# psoc4axx register map
Vendor: Cypress Semiconductor; Series: PSoC4Axx; File version: 1.0
CPU: CM0PLUS r0p1, little endian, no MPU, no FPU, VTOR, 2 interrupt priority bits
Registers are 32-bit, read-write, reset 0x0 unless marked. A register's access mark holds for its fields unless they carry their own. Offsets are from the block's base; [hi:lo] are bit positions; {n}, {i} and the like mark numbered series.

## ART0 — Analog Routing Block
Base 0x40380000
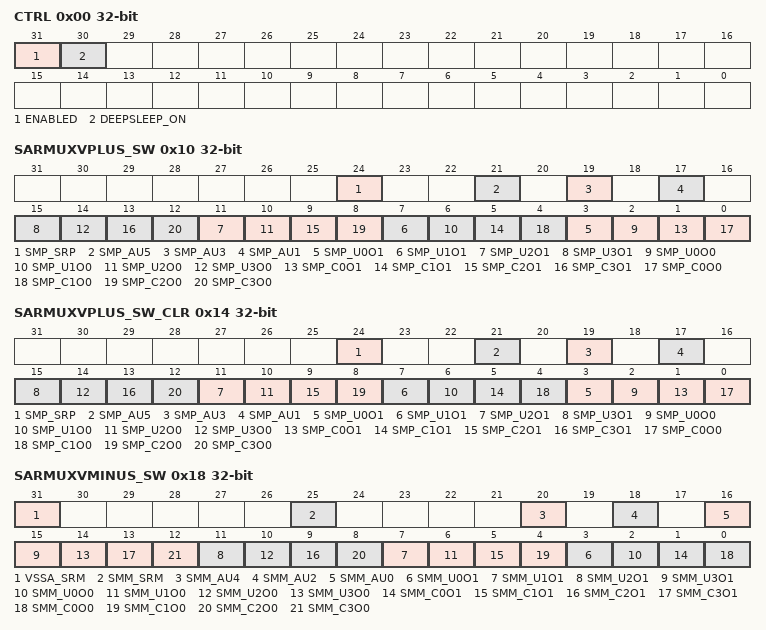
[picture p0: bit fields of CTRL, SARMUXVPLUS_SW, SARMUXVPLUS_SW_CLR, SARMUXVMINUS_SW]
0x00 CTRL — global AROUTE control
  [31] ENABLED — - 0: AROUTE IP disabled (put analog in power down, open all switches) - 1: AROUTE IP enabled
  [30] DEEPSLEEP_ON — - 0: AROUTE IP disabled off during DeepSleep power mode - 1: AROUTE IP remains enabled during DeepSleep power mode (if ENABLED=1)
0x10 SARMUXVPLUS_SW — sarmux_vplus switch control
  [24] SMP_SRP — connect sarmux_vplus to sar_vplus
  [21] SMP_AU5 — connect sarmux_vplus to acore_u5
  [19] SMP_AU3 — connect sarmux_vplus to acore_u3
  [17] SMP_AU1 — connect sarmux_vplus to acore_u1
  [4n+3] SMP_U{n}O1 (n=0..3) — connect sarmux_vplus to uab{n}_vout1
  [4n+2] SMP_U{n}O0 (n=0..3) — connect sarmux_vplus to uab{n}_vout0
  [4n+1] SMP_C{n}O1 (n=0..3) — connect sarmux_vplus to ctb{n}_vout1
  [4n] SMP_C{n}O0 (n=0..3) — connect sarmux_vplus to ctb{n}_vout0
0x14 SARMUXVPLUS_SW_CLR — sarmux_vplus switch control clear
  [24] SMP_SRP — clear sarmux_vplus to sar_vplus
  [21] SMP_AU5 — clear sarmux_vplus to acore_u5
  [19] SMP_AU3 — clear sarmux_vplus to acore_u3
  [17] SMP_AU1 — clear sarmux_vplus to acore_u1
  [4n+3] SMP_U{n}O1 (n=0..3) — clear sarmux_vplus to uab{n}_vout1
  [4n+2] SMP_U{n}O0 (n=0..3) — clear sarmux_vplus to uab{n}_vout0
  [4n+1] SMP_C{n}O1 (n=0..3) — clear sarmux_vplus to ctb{n}_vout1
  [4n] SMP_C{n}O0 (n=0..3) — clear sarmux_vplus to ctb{n}_vout0
0x18 SARMUXVMINUS_SW — sarmux_vminus switch control
  [31] VSSA_SRM — connect vssa to sar_vminus
  [25] SMM_SRM — connect sarmux_vminus to sar_vminus
  [20] SMM_AU4 — connect sarmux_vminus to acore_u4
  [18] SMM_AU2 — connect sarmux_vminus to acore_u2
  [16] SMM_AU0 — connect sarmux_vminus to acore_u0
  [4n+3] SMM_U{n}O1 (n=0..3) — connect sarmux_vminus to uab{n}_vout1
  [4n+2] SMM_U{n}O0 (n=0..3) — connect sarmux_vminus to uab{n}_vout0
  [4n+1] SMM_C{n}O1 (n=0..3) — connect sarmux_vminus to ctb{n}_vout1
  [4n] SMM_C{n}O0 (n=0..3) — connect sarmux_vminus to ctb{n}_vout0
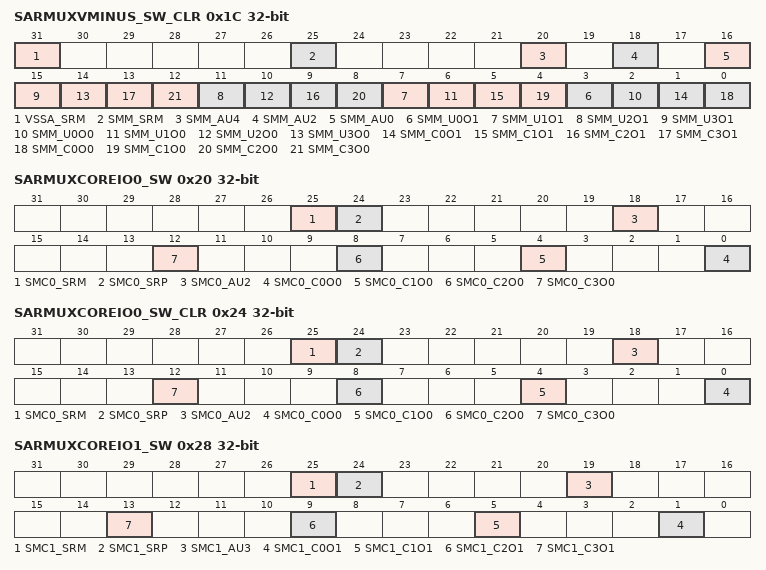
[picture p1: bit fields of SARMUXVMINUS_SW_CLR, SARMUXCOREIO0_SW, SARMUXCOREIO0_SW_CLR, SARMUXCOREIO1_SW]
0x1C SARMUXVMINUS_SW_CLR — sarmux_vminus switch control clear
  [31] VSSA_SRM — clear vssa to sar_vminus
  [25] SMM_SRM — clear sarmux_vminus to sar_vminus
  [20] SMM_AU4 — clear sarmux_vminus to acore_u4
  [18] SMM_AU2 — clear sarmux_vminus to acore_u2
  [16] SMM_AU0 — clear sarmux_vminus to acore_u0
  [4n+3] SMM_U{n}O1 (n=0..3) — clear sarmux_vminus to uab{n}_vout1
  [4n+2] SMM_U{n}O0 (n=0..3) — clear sarmux_vminus to uab{n}_vout0
  [4n+1] SMM_C{n}O1 (n=0..3) — clear sarmux_vminus to ctb{n}_vout1
  [4n] SMM_C{n}O0 (n=0..3) — clear sarmux_vminus to ctb{n}_vout0
0x20 SARMUXCOREIO0_SW — sarmux_coreio0 switch control
  [25] SMC0_SRM — connect sarmux_coreio0 to sar_vminus
  [24] SMC0_SRP — connect sarmux_coreio0 to sar_vplus
  [18] SMC0_AU2 — connect sarmux_coreio0 to acore_u2
  [4n] SMC0_C{n}O0 (n=0..3) — connect sarmux_coreio0 to ctb{n}_vout0
0x24 SARMUXCOREIO0_SW_CLR — sarmux_coreio0 switch control clear
  [25] SMC0_SRM — clear sarmux_coreio0 to sar_vminus
  [24] SMC0_SRP — clear sarmux_coreio0 to sar_vplus
  [18] SMC0_AU2 — clear sarmux_coreio0 to acore_u2
  [4n] SMC0_C{n}O0 (n=0..3) — clear sarmux_coreio0 to ctb{n}_vout0
0x28 SARMUXCOREIO1_SW — sarmux_coreio1 switch control
  [25] SMC1_SRM — connect sarmux_coreio1 to sar_vminus
  [24] SMC1_SRP — connect sarmux_coreio1 to sar_vplus
  [19] SMC1_AU3 — connect sarmux_coreio1 to acore_u3
  [4n+1] SMC1_C{n}O1 (n=0..3) — connect sarmux_coreio1 to ctb{n}_vout1
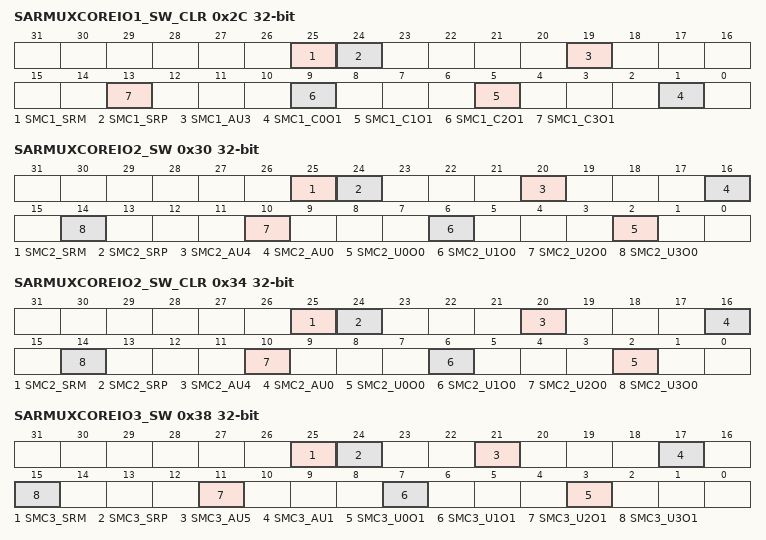
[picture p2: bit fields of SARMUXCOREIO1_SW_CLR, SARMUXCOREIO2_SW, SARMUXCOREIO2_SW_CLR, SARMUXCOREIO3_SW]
0x2C SARMUXCOREIO1_SW_CLR — sarmux_coreio1 switch control clear
  [25] SMC1_SRM — clear sarmux_coreio1 to sar_vminus
  [24] SMC1_SRP — clear sarmux_coreio1 to sar_vplus
  [19] SMC1_AU3 — clear sarmux_coreio1 to acore_u3
  [4n+1] SMC1_C{n}O1 (n=0..3) — clear sarmux_coreio1 to ctb{n}_vout1
0x30 SARMUXCOREIO2_SW — sarmux_coreio2 switch control
  [25] SMC2_SRM — connect sarmux_coreio2 to sar_vminus
  [24] SMC2_SRP — connect sarmux_coreio2 to sar_vplus
  [20] SMC2_AU4 — connect sarmux_coreio2 to acore_u4
  [16] SMC2_AU0 — connect sarmux_coreio2 to acore_u0
  [4n+2] SMC2_U{n}O0 (n=0..3) — connect sarmux_coreio2 to uab{n}_vout0
0x34 SARMUXCOREIO2_SW_CLR — sarmux_coreio2 switch control clear
  [25] SMC2_SRM — clear sarmux_coreio2 to sar_vminus
  [24] SMC2_SRP — clear sarmux_coreio2 to sar_vplus
  [20] SMC2_AU4 — clear sarmux_coreio2 to acore_u4
  [16] SMC2_AU0 — clear sarmux_coreio2 to acore_u0
  [4n+2] SMC2_U{n}O0 (n=0..3) — clear sarmux_coreio2 to uab{n}_vout0
0x38 SARMUXCOREIO3_SW — sarmux_coreio3 switch control
  [25] SMC3_SRM — connect sarmux_coreio3 to sar_vminus
  [24] SMC3_SRP — connect sarmux_coreio3 to sar_vplus
  [21] SMC3_AU5 — connect sarmux_coreio3 to acore_u5
  [17] SMC3_AU1 — connect sarmux_coreio3 to acore_u1
  [4n+3] SMC3_U{n}O1 (n=0..3) — connect sarmux_coreio3 to uab{n}_vout1
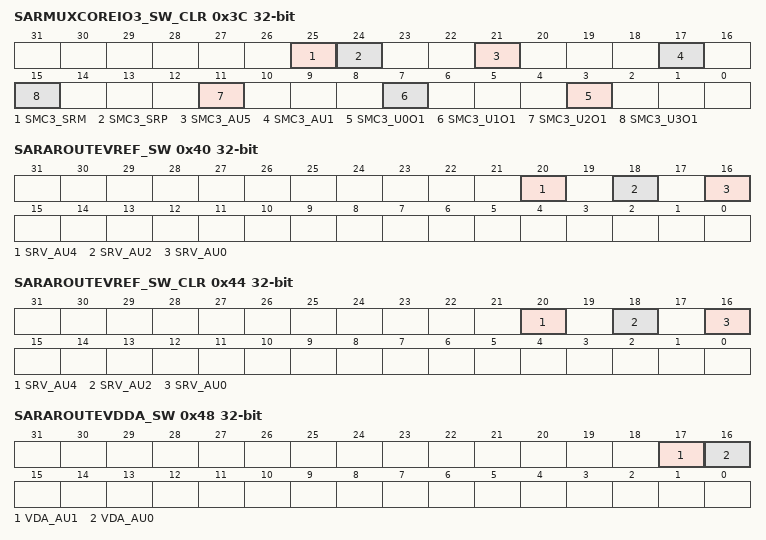
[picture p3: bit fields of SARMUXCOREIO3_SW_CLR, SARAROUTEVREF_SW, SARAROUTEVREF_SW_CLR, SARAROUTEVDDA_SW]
0x3C SARMUXCOREIO3_SW_CLR — sarmux_coreio3 switch control clear
  [25] SMC3_SRM — clear sarmux_coreio3 to sar_vminus
  [24] SMC3_SRP — clear sarmux_coreio3 to sar_vplus
  [21] SMC3_AU5 — clear sarmux_coreio3 to acore_u5
  [17] SMC3_AU1 — clear sarmux_coreio3 to acore_u1
  [4n+3] SMC3_U{n}O1 (n=0..3) — clear sarmux_coreio3 to uab{n}_vout1
0x40 SARAROUTEVREF_SW — sar_aroute_vref switch control
  [20] SRV_AU4 — connect sar_aroute_vref to acore_u4
  [18] SRV_AU2 — connect sar_aroute_vref to acore_u2
  [16] SRV_AU0 — connect sar_aroute_vref to acore_u0
0x44 SARAROUTEVREF_SW_CLR — sar_aroute_vref switch control clear
  [20] SRV_AU4 — clear sar_aroute_vref to acore_u4
  [18] SRV_AU2 — clear sar_aroute_vref to acore_u2
  [16] SRV_AU0 — clear sar_aroute_vref to acore_u0
0x48 SARAROUTEVDDA_SW — sar_aroute_vdda switch control
  [17] VDA_AU1 — connect sar_aroute_vdda to acore_u1
  [16] VDA_AU0 — connect sar_aroute_vdda to acore_u0
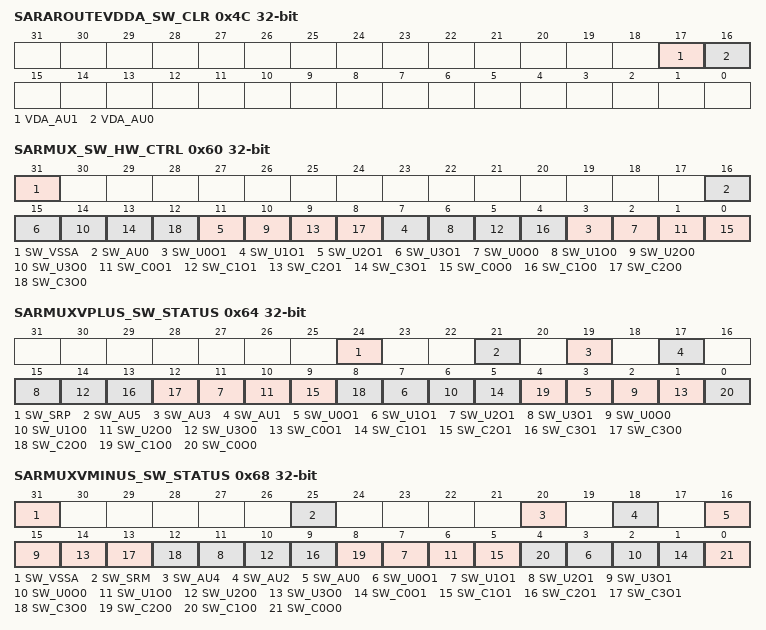
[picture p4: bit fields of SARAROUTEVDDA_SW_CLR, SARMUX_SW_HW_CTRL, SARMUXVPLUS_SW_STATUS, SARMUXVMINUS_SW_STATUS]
0x4C SARAROUTEVDDA_SW_CLR — sar_aroute_vdda switch control clear
  [17] VDA_AU1 — clear sar_aroute_vdda to acore_u1
  [16] VDA_AU0 — clear sar_aroute_vdda to acore_u0
0x60 SARMUX_SW_HW_CTRL — AROUTE SARMUX VPLUS/VMINUS hardware control
  [31] SW_VSSA, [16] SW_AU0, [4n+3] SW_U{n}O1 (n=0..3), [4n+2] SW_U{n}O0 (n=0..3), [4n+1] SW_C{n}O1 (n=0..3), [4n] SW_C{n}O0 (n=0..3)
0x64 SARMUXVPLUS_SW_STATUS ro — AROUTE SARMUX VPLUS switch control status
  [24] SW_SRP — connect sarmux_vplus to sar_vplus
  [21] SW_AU5 — connect sarmux_vplus to acore_u5
  [19] SW_AU3 — connect sarmux_vplus to acore_u3
  [17] SW_AU1 — connect sarmux_vplus to acore_u1
  [4n+3] SW_U{n}O1 (n=0..3)
  [4n+2] SW_U{n}O0 (n=0..3)
  [4n+1] SW_C{n}O1 (n=0..3)
  [12] SW_C3O0
  [8] SW_C2O0
  [4] SW_C1O0
  [0] SW_C0O0 — see corresponding bit in ART_SARVPLUS_SW
0x68 SARMUXVMINUS_SW_STATUS ro — AROUTE SAR VMINUS switch control status
  [31] SW_VSSA
  [25] SW_SRM
  [20] SW_AU4
  [18] SW_AU2
  [16] SW_AU0
  [4n+3] SW_U{n}O1 (n=0..3)
  [4n+2] SW_U{n}O0 (n=0..3)
  [4n+1] SW_C{n}O1 (n=0..3)
  [12] SW_C3O0
  [8] SW_C2O0
  [4] SW_C1O0
  [0] SW_C0O0 — see corresponding bit in ART_SARVMINUS_SW
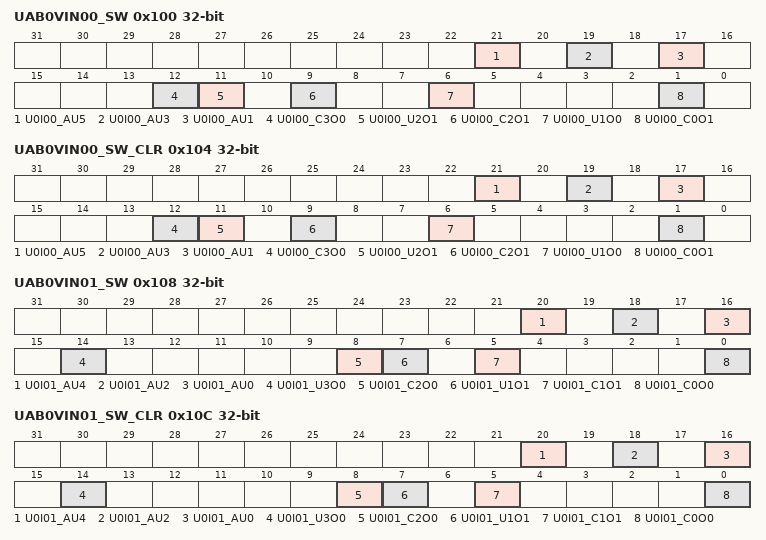
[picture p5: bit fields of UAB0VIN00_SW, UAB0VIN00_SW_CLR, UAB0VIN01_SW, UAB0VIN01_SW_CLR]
0x100 UAB0VIN00_SW — uab0_vin00 switch control
  [21] U0I00_AU5 — connect uab0_vin00 to acore_u5
  [19] U0I00_AU3 — connect uab0_vin00 to acore_u3
  [17] U0I00_AU1 — connect uab0_vin00 to acore_u1
  [12] U0I00_C3O0 — connect uab0_vin00 to ctb3_vout0
  [11] U0I00_U2O1 — connect uab0_vin00 to uab2_vout1
  [9] U0I00_C2O1 — connect uab0_vin00 to ctb2_vout1
  [6] U0I00_U1O0 — connect uab0_vin00 to uab1_vout0
  [1] U0I00_C0O1 — connect uab0_vin00 to ctb0_vout1
0x104 UAB0VIN00_SW_CLR — uab0_vin00 switch control clear
  [21] U0I00_AU5 — clear uab0_vin00 to acore_u5
  [19] U0I00_AU3 — clear uab0_vin00 to acore_u3
  [17] U0I00_AU1 — clear uab0_vin00 to acore_u1
  [12] U0I00_C3O0 — clear uab0_vin00 to ctb3_vout0
  [11] U0I00_U2O1 — clear uab0_vin00 to uab2_vout1
  [9] U0I00_C2O1 — clear uab0_vin00 to ctb2_vout1
  [6] U0I00_U1O0 — clear uab0_vin00 to uab1_vout0
  [1] U0I00_C0O1 — clear uab0_vin00 to ctb0_vout1
0x108 UAB0VIN01_SW — uab0_vin01 switch control
  [20] U0I01_AU4 — connect uab0_vin01 to acore_u4
  [18] U0I01_AU2 — connect uab0_vin01 to acore_u2
  [16] U0I01_AU0 — connect uab0_vin01 to acore_u0
  [14] U0I01_U3O0 — connect uab0_vin01 to uab3_vout0
  [8] U0I01_C2O0 — connect uab0_vin01 to ctb2_vout0
  [7] U0I01_U1O1 — connect uab0_vin01 to uab1_vout1
  [5] U0I01_C1O1 — connect uab0_vin01 to ctb1_vout1
  [0] U0I01_C0O0 — connect uab0_vin01 to ctb0_vout0
0x10C UAB0VIN01_SW_CLR — uab0_vin01 switch control clear
  [20] U0I01_AU4 — clear uab0_vin01 to acore_u4
  [18] U0I01_AU2 — clear uab0_vin01 to acore_u2
  [16] U0I01_AU0 — clear uab0_vin01 to acore_u0
  [14] U0I01_U3O0 — clear uab0_vin01 to uab3_vout0
  [8] U0I01_C2O0 — clear uab0_vin01 to ctb2_vout0
  [7] U0I01_U1O1 — clear uab0_vin01 to uab1_vout1
  [5] U0I01_C1O1 — clear uab0_vin01 to ctb1_vout1
  [0] U0I01_C0O0 — clear uab0_vin01 to ctb0_vout0
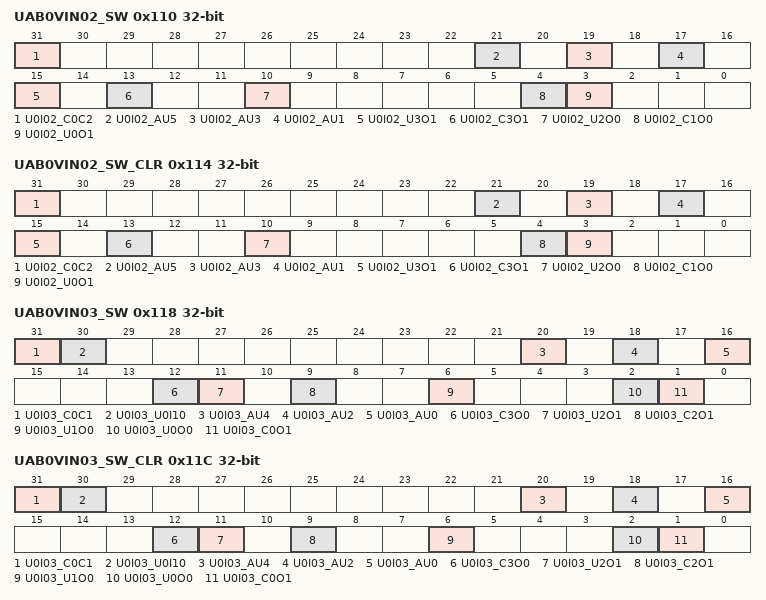
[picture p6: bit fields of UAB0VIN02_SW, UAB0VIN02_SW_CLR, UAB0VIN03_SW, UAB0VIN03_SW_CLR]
0x110 UAB0VIN02_SW — uab0_vin02 switch control
  [31] U0I02_C0C2 — connect uab0_vin02 to ctb0_ctbus2
  [21] U0I02_AU5 — connect uab0_vin02 to acore_u5
  [19] U0I02_AU3 — connect uab0_vin02 to acore_u3
  [17] U0I02_AU1 — connect uab0_vin02 to acore_u1
  [15] U0I02_U3O1 — connect uab0_vin02 to uab3_vout1
  [13] U0I02_C3O1 — connect uab0_vin02 to ctb3_vout1
  [10] U0I02_U2O0 — connect uab0_vin02 to uab2_vout0
  [4] U0I02_C1O0 — connect uab0_vin02 to ctb1_vout0
  [3] U0I02_U0O1 — connect uab0_vin02 to uab0_vout1
0x114 UAB0VIN02_SW_CLR — uab0_vin02 switch control clear
  [31] U0I02_C0C2 — clear uab0_vin02 to ctb0_ctbus2
  [21] U0I02_AU5 — clear uab0_vin02 to acore_u5
  [19] U0I02_AU3 — clear uab0_vin02 to acore_u3
  [17] U0I02_AU1 — clear uab0_vin02 to acore_u1
  [15] U0I02_U3O1 — clear uab0_vin02 to uab3_vout1
  [13] U0I02_C3O1 — clear uab0_vin02 to ctb3_vout1
  [10] U0I02_U2O0 — clear uab0_vin02 to uab2_vout0
  [4] U0I02_C1O0 — clear uab0_vin02 to ctb1_vout0
  [3] U0I02_U0O1 — clear uab0_vin02 to uab0_vout1
0x118 UAB0VIN03_SW — uab0_vin03 switch control
  [31] U0I03_C0C1 — connect uab0_vin03 to ctb0_ctbus1
  [30] U0I03_U0I10 — connect uab0_vin03 to uab0_vin10
  [20] U0I03_AU4 — connect uab0_vin03 to acore_u4
  [18] U0I03_AU2 — connect uab0_vin03 to acore_u2
  [16] U0I03_AU0 — connect uab0_vin03 to acore_u0
  [12] U0I03_C3O0 — connect uab0_vin03 to ctb3_vout0
  [11] U0I03_U2O1 — connect uab0_vin03 to uab2_vout1
  [9] U0I03_C2O1 — connect uab0_vin03 to ctb2_vout1
  [6] U0I03_U1O0 — connect uab0_vin03 to uab1_vout0
  [2] U0I03_U0O0 — connect uab0_vin03 to uab0_vout0
  [1] U0I03_C0O1 — connect uab0_vin03 to ctb0_vout1
0x11C UAB0VIN03_SW_CLR — uab0_vin03 switch control clear
  [31] U0I03_C0C1 — clear uab0_vin03 to ctb0_ctbus1
  [30] U0I03_U0I10 — clear uab0_vin03 to uab0_vin10
  [20] U0I03_AU4 — clear uab0_vin03 to acore_u4
  [18] U0I03_AU2 — clear uab0_vin03 to acore_u2
  [16] U0I03_AU0 — clear uab0_vin03 to acore_u0
  [12] U0I03_C3O0 — clear uab0_vin03 to ctb3_vout0
  [11] U0I03_U2O1 — clear uab0_vin03 to uab2_vout1
  [9] U0I03_C2O1 — clear uab0_vin03 to ctb2_vout1
  [6] U0I03_U1O0 — clear uab0_vin03 to uab1_vout0
  [2] U0I03_U0O0 — clear uab0_vin03 to uab0_vout0
  [1] U0I03_C0O1 — clear uab0_vin03 to ctb0_vout1
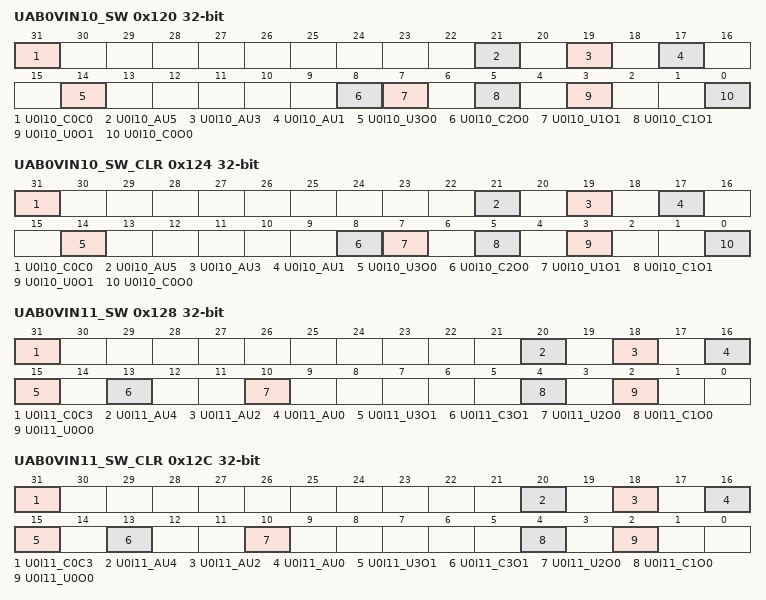
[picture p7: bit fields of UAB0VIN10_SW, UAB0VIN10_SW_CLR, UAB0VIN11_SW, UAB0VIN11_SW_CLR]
0x120 UAB0VIN10_SW — uab0_vin10 switch control
  [31] U0I10_C0C0 — connect uab0_vin10 to ctb0_ctbus0
  [21] U0I10_AU5 — connect uab0_vin10 to acore_u5
  [19] U0I10_AU3 — connect uab0_vin10 to acore_u3
  [17] U0I10_AU1 — connect uab0_vin10 to acore_u1
  [14] U0I10_U3O0 — connect uab0_vin10 to uab3_vout0
  [8] U0I10_C2O0 — connect uab0_vin10 to ctb2_vout0
  [7] U0I10_U1O1 — connect uab0_vin10 to uab1_vout1
  [5] U0I10_C1O1 — connect uab0_vin10 to ctb1_vout1
  [3] U0I10_U0O1 — connect uab0_vin10 to uab0_vout1
  [0] U0I10_C0O0 — connect uab0_vin10 to ctb0_vout0
0x124 UAB0VIN10_SW_CLR — uab0_vin10 switch control clear
  [31] U0I10_C0C0 — clear uab0_vin10 to ctb0_ctbus0
  [21] U0I10_AU5 — clear uab0_vin10 to acore_u5
  [19] U0I10_AU3 — clear uab0_vin10 to acore_u3
  [17] U0I10_AU1 — clear uab0_vin10 to acore_u1
  [14] U0I10_U3O0 — clear uab0_vin10 to uab3_vout0
  [8] U0I10_C2O0 — clear uab0_vin10 to ctb2_vout0
  [7] U0I10_U1O1 — clear uab0_vin10 to uab1_vout1
  [5] U0I10_C1O1 — clear uab0_vin10 to ctb1_vout1
  [3] U0I10_U0O1 — clear uab0_vin10 to uab0_vout1
  [0] U0I10_C0O0 — clear uab0_vin10 to ctb0_vout0
0x128 UAB0VIN11_SW — uab0_vin11 switch control
  [31] U0I11_C0C3 — connect uab0_vin11 to ctb0_ctbus3
  [20] U0I11_AU4 — connect uab0_vin11 to acore_u4
  [18] U0I11_AU2 — connect uab0_vin11 to acore_u2
  [16] U0I11_AU0 — connect uab0_vin11 to acore_u0
  [15] U0I11_U3O1 — connect uab0_vin11 to uab3_vout1
  [13] U0I11_C3O1 — connect uab0_vin11 to ctb3_vout1
  [10] U0I11_U2O0 — connect uab0_vin11 to uab2_vout0
  [4] U0I11_C1O0 — connect uab0_vin11 to ctb1_vout0
  [2] U0I11_U0O0 — connect uab0_vin11 to uab0_vout0
0x12C UAB0VIN11_SW_CLR — uab0_vin11 switch control clear
  [31] U0I11_C0C3 — clear uab0_vin11 to ctb0_ctbus3
  [20] U0I11_AU4 — clear uab0_vin11 to acore_u4
  [18] U0I11_AU2 — clear uab0_vin11 to acore_u2
  [16] U0I11_AU0 — clear uab0_vin11 to acore_u0
  [15] U0I11_U3O1 — clear uab0_vin11 to uab3_vout1
  [13] U0I11_C3O1 — clear uab0_vin11 to ctb3_vout1
  [10] U0I11_U2O0 — clear uab0_vin11 to uab2_vout0
  [4] U0I11_C1O0 — clear uab0_vin11 to ctb1_vout0
  [2] U0I11_U0O0 — clear uab0_vin11 to uab0_vout0
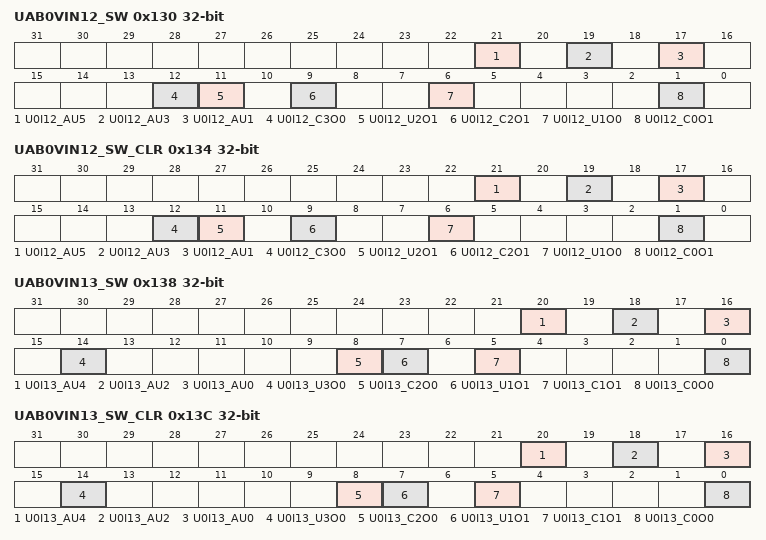
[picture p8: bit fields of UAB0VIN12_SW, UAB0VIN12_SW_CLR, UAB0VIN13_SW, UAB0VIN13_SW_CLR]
0x130 UAB0VIN12_SW — uab0_vin12 switch control
  [21] U0I12_AU5 — connect uab0_vin12 to acore_u5
  [19] U0I12_AU3 — connect uab0_vin12 to acore_u3
  [17] U0I12_AU1 — connect uab0_vin12 to acore_u1
  [12] U0I12_C3O0 — connect uab0_vin12 to ctb3_vout0
  [11] U0I12_U2O1 — connect uab0_vin12 to uab2_vout1
  [9] U0I12_C2O1 — connect uab0_vin12 to ctb2_vout1
  [6] U0I12_U1O0 — connect uab0_vin12 to uab1_vout0
  [1] U0I12_C0O1 — connect uab0_vin12 to ctb0_vout1
0x134 UAB0VIN12_SW_CLR — uab0_vin12 switch control clear
  [21] U0I12_AU5 — clear uab0_vin12 to acore_u5
  [19] U0I12_AU3 — clear uab0_vin12 to acore_u3
  [17] U0I12_AU1 — clear uab0_vin12 to acore_u1
  [12] U0I12_C3O0 — clear uab0_vin12 to ctb3_vout0
  [11] U0I12_U2O1 — clear uab0_vin12 to uab2_vout1
  [9] U0I12_C2O1 — clear uab0_vin12 to ctb2_vout1
  [6] U0I12_U1O0 — clear uab0_vin12 to uab1_vout0
  [1] U0I12_C0O1 — clear uab0_vin12 to ctb0_vout1
0x138 UAB0VIN13_SW — uab0_vin13 switch control
  [20] U0I13_AU4 — connect uab0_vin13 to acore_u4
  [18] U0I13_AU2 — connect uab0_vin13 to acore_u2
  [16] U0I13_AU0 — connect uab0_vin13 to acore_u0
  [14] U0I13_U3O0 — connect uab0_vin13 to uab3_vout0
  [8] U0I13_C2O0 — connect uab0_vin13 to ctb2_vout0
  [7] U0I13_U1O1 — connect uab0_vin13 to uab1_vout1
  [5] U0I13_C1O1 — connect uab0_vin13 to ctb1_vout1
  [0] U0I13_C0O0 — connect uab0_vin13 to ctb0_vout0
0x13C UAB0VIN13_SW_CLR — uab0_vin13 switch control clear
  [20] U0I13_AU4 — clear uab0_vin13 to acore_u4
  [18] U0I13_AU2 — clear uab0_vin13 to acore_u2
  [16] U0I13_AU0 — clear uab0_vin13 to acore_u0
  [14] U0I13_U3O0 — clear uab0_vin13 to uab3_vout0
  [8] U0I13_C2O0 — clear uab0_vin13 to ctb2_vout0
  [7] U0I13_U1O1 — clear uab0_vin13 to uab1_vout1
  [5] U0I13_C1O1 — clear uab0_vin13 to ctb1_vout1
  [0] U0I13_C0O0 — clear uab0_vin13 to ctb0_vout0
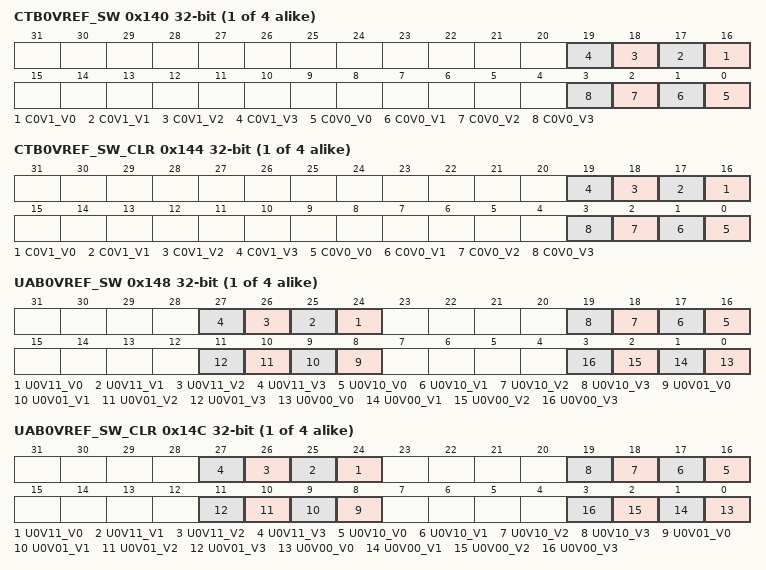
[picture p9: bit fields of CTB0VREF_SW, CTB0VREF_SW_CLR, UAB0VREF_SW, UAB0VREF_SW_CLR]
{0x140+0x80*i} CTB{i}VREF_SW (i=0..3) — ctb{i}_vref0 switch control
  [n+16] C{i}V1_V{n} (n=0..3) — connect ctb{i}_vref1 to vref{n}
  [n] C{i}V0_V{n} (n=0..3) — connect ctb{i}_vref0 to vref{n}
{0x144+0x80*i} CTB{i}VREF_SW_CLR (i=0..3) — ctb{i}_vref0 switch control clear
  [n+16] C{i}V1_V{n} (n=0..3) — clear ctb{i}_vref1 to vref{n}
  [n] C{i}V0_V{n} (n=0..3) — clear ctb{i}_vref0 to vref{n}
{0x148+0x80*i} UAB{i}VREF_SW (i=0..3) — uab{i}_vref00 switch control
  [n+24] U{i}V11_V{n} (n=0..3) — connect uab{i}_vref11 to vref{n}
  [n+16] U{i}V10_V{n} (n=0..3) — connect uab{i}_vref10 to vref{n}
  [n+8] U{i}V01_V{n} (n=0..3) — connect uab{i}_vref01 to vref{n}
  [n] U{i}V00_V{n} (n=0..3) — connect uab{i}_vref00 to vref{n}
{0x14C+0x80*i} UAB{i}VREF_SW_CLR (i=0..3) — uab{i}_vref00 switch control clear
  [n+24] U{i}V11_V{n} (n=0..3) — clear uab{i}_vref11 to vref{n}
  [n+16] U{i}V10_V{n} (n=0..3) — clear uab{i}_vref10 to vref{n}
  [n+8] U{i}V01_V{n} (n=0..3) — clear uab{i}_vref01 to vref{n}
  [n] U{i}V00_V{n} (n=0..3) — clear uab{i}_vref00 to vref{n}
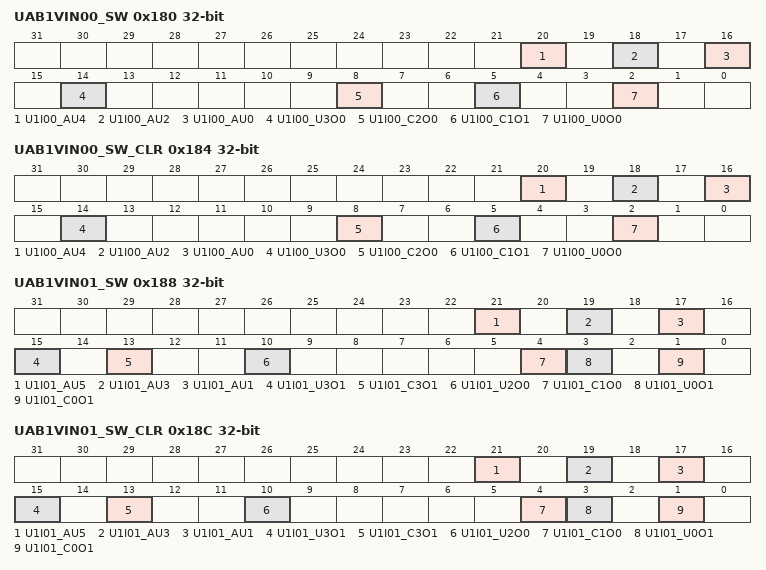
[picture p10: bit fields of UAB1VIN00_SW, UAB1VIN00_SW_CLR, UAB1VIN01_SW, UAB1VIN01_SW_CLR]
0x180 UAB1VIN00_SW — uab1_vin00 switch control
  [20] U1I00_AU4 — connect uab1_vin00 to acore_u4
  [18] U1I00_AU2 — connect uab1_vin00 to acore_u2
  [16] U1I00_AU0 — connect uab1_vin00 to acore_u0
  [14] U1I00_U3O0 — connect uab1_vin00 to uab3_vout0
  [8] U1I00_C2O0 — connect uab1_vin00 to ctb2_vout0
  [5] U1I00_C1O1 — connect uab1_vin00 to ctb1_vout1
  [2] U1I00_U0O0 — connect uab1_vin00 to uab0_vout0
0x184 UAB1VIN00_SW_CLR — uab1_vin00 switch control clear
  [20] U1I00_AU4 — clear uab1_vin00 to acore_u4
  [18] U1I00_AU2 — clear uab1_vin00 to acore_u2
  [16] U1I00_AU0 — clear uab1_vin00 to acore_u0
  [14] U1I00_U3O0 — clear uab1_vin00 to uab3_vout0
  [8] U1I00_C2O0 — clear uab1_vin00 to ctb2_vout0
  [5] U1I00_C1O1 — clear uab1_vin00 to ctb1_vout1
  [2] U1I00_U0O0 — clear uab1_vin00 to uab0_vout0
0x188 UAB1VIN01_SW — uab1_vin01 switch control
  [21] U1I01_AU5 — connect uab1_vin01 to acore_u5
  [19] U1I01_AU3 — connect uab1_vin01 to acore_u3
  [17] U1I01_AU1 — connect uab1_vin01 to acore_u1
  [15] U1I01_U3O1 — connect uab1_vin01 to uab3_vout1
  [13] U1I01_C3O1 — connect uab1_vin01 to ctb3_vout1
  [10] U1I01_U2O0 — connect uab1_vin01 to uab2_vout0
  [4] U1I01_C1O0 — connect uab1_vin01 to ctb1_vout0
  [3] U1I01_U0O1 — connect uab1_vin01 to uab0_vout1
  [1] U1I01_C0O1 — connect uab1_vin01 to ctb0_vout1
0x18C UAB1VIN01_SW_CLR — uab1_vin01 switch control clear
  [21] U1I01_AU5 — clear uab1_vin01 to acore_u5
  [19] U1I01_AU3 — clear uab1_vin01 to acore_u3
  [17] U1I01_AU1 — clear uab1_vin01 to acore_u1
  [15] U1I01_U3O1 — clear uab1_vin01 to uab3_vout1
  [13] U1I01_C3O1 — clear uab1_vin01 to ctb3_vout1
  [10] U1I01_U2O0 — clear uab1_vin01 to uab2_vout0
  [4] U1I01_C1O0 — clear uab1_vin01 to ctb1_vout0
  [3] U1I01_U0O1 — clear uab1_vin01 to uab0_vout1
  [1] U1I01_C0O1 — clear uab1_vin01 to ctb0_vout1
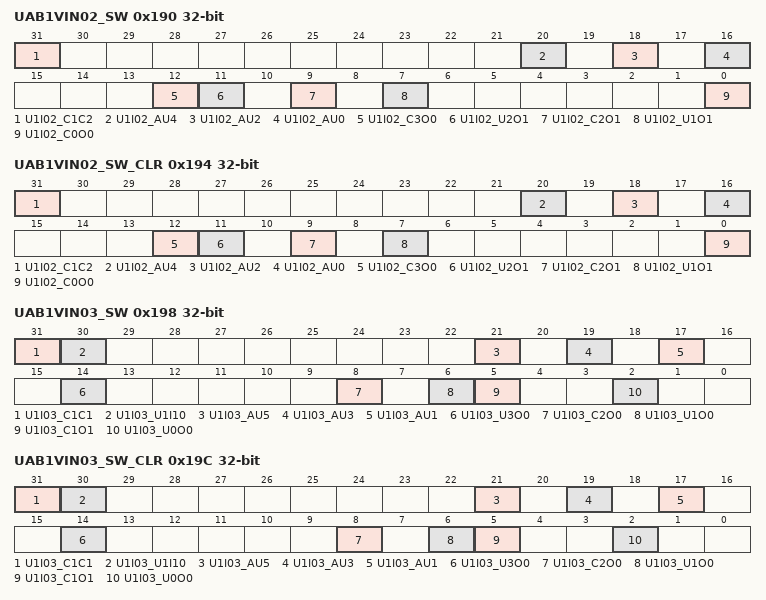
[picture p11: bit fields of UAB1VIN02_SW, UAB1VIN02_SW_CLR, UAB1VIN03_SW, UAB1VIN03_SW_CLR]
0x190 UAB1VIN02_SW — uab1_vin02 switch control
  [31] U1I02_C1C2 — connect uab1_vin02 to ctb1_ctbus2
  [20] U1I02_AU4 — connect uab1_vin02 to acore_u4
  [18] U1I02_AU2 — connect uab1_vin02 to acore_u2
  [16] U1I02_AU0 — connect uab1_vin02 to acore_u0
  [12] U1I02_C3O0 — connect uab1_vin02 to ctb3_vout0
  [11] U1I02_U2O1 — connect uab1_vin02 to uab2_vout1
  [9] U1I02_C2O1 — connect uab1_vin02 to ctb2_vout1
  [7] U1I02_U1O1 — connect uab1_vin02 to uab1_vout1
  [0] U1I02_C0O0 — connect uab1_vin02 to ctb0_vout0
0x194 UAB1VIN02_SW_CLR — uab1_vin02 switch control clear
  [31] U1I02_C1C2 — clear uab1_vin02 to ctb1_ctbus2
  [20] U1I02_AU4 — clear uab1_vin02 to acore_u4
  [18] U1I02_AU2 — clear uab1_vin02 to acore_u2
  [16] U1I02_AU0 — clear uab1_vin02 to acore_u0
  [12] U1I02_C3O0 — clear uab1_vin02 to ctb3_vout0
  [11] U1I02_U2O1 — clear uab1_vin02 to uab2_vout1
  [9] U1I02_C2O1 — clear uab1_vin02 to ctb2_vout1
  [7] U1I02_U1O1 — clear uab1_vin02 to uab1_vout1
  [0] U1I02_C0O0 — clear uab1_vin02 to ctb0_vout0
0x198 UAB1VIN03_SW — uab1_vin03 switch control
  [31] U1I03_C1C1 — connect uab1_vin03 to ctb1_ctbus1
  [30] U1I03_U1I10 — connect uab1_vin03 to uab1_vin10
  [21] U1I03_AU5 — connect uab1_vin03 to acore_u5
  [19] U1I03_AU3 — connect uab1_vin03 to acore_u3
  [17] U1I03_AU1 — connect uab1_vin03 to acore_u1
  [14] U1I03_U3O0 — connect uab1_vin03 to uab3_vout0
  [8] U1I03_C2O0 — connect uab1_vin03 to ctb2_vout0
  [6] U1I03_U1O0 — connect uab1_vin03 to uab1_vout0
  [5] U1I03_C1O1 — connect uab1_vin03 to ctb1_vout1
  [2] U1I03_U0O0 — connect uab1_vin03 to uab0_vout0
0x19C UAB1VIN03_SW_CLR — uab1_vin03 switch control clear
  [31] U1I03_C1C1 — clear uab1_vin03 to ctb1_ctbus1
  [30] U1I03_U1I10 — clear uab1_vin03 to uab1_vin10
  [21] U1I03_AU5 — clear uab1_vin03 to acore_u5
  [19] U1I03_AU3 — clear uab1_vin03 to acore_u3
  [17] U1I03_AU1 — clear uab1_vin03 to acore_u1
  [14] U1I03_U3O0 — clear uab1_vin03 to uab3_vout0
  [8] U1I03_C2O0 — clear uab1_vin03 to ctb2_vout0
  [6] U1I03_U1O0 — clear uab1_vin03 to uab1_vout0
  [5] U1I03_C1O1 — clear uab1_vin03 to ctb1_vout1
  [2] U1I03_U0O0 — clear uab1_vin03 to uab0_vout0
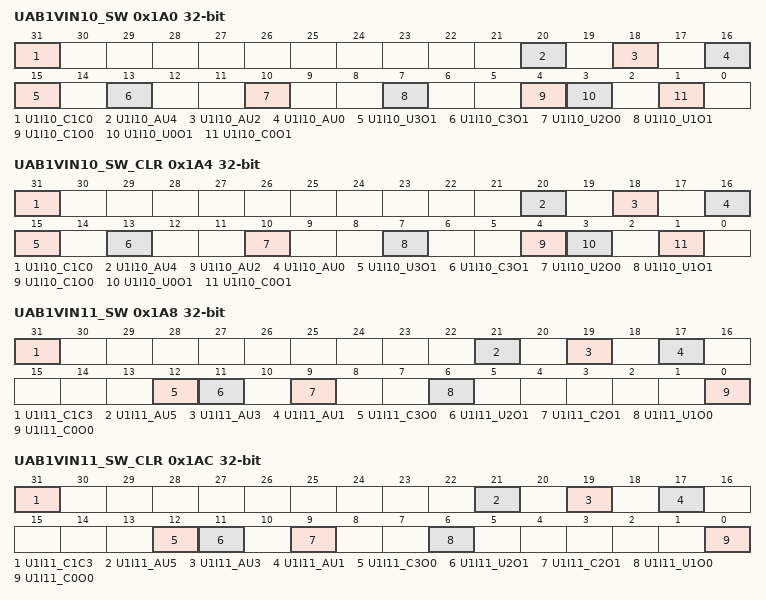
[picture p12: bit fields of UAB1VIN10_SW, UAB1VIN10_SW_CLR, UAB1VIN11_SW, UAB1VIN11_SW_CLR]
0x1A0 UAB1VIN10_SW — uab1_vin10 switch control
  [31] U1I10_C1C0 — connect uab1_vin10 to ctb1_ctbus0
  [20] U1I10_AU4 — connect uab1_vin10 to acore_u4
  [18] U1I10_AU2 — connect uab1_vin10 to acore_u2
  [16] U1I10_AU0 — connect uab1_vin10 to acore_u0
  [15] U1I10_U3O1 — connect uab1_vin10 to uab3_vout1
  [13] U1I10_C3O1 — connect uab1_vin10 to ctb3_vout1
  [10] U1I10_U2O0 — connect uab1_vin10 to uab2_vout0
  [7] U1I10_U1O1 — connect uab1_vin10 to uab1_vout1
  [4] U1I10_C1O0 — connect uab1_vin10 to ctb1_vout0
  [3] U1I10_U0O1 — connect uab1_vin10 to uab0_vout1
  [1] U1I10_C0O1 — connect uab1_vin10 to ctb0_vout1
0x1A4 UAB1VIN10_SW_CLR — uab1_vin10 switch control clear
  [31] U1I10_C1C0 — clear uab1_vin10 to ctb1_ctbus0
  [20] U1I10_AU4 — clear uab1_vin10 to acore_u4
  [18] U1I10_AU2 — clear uab1_vin10 to acore_u2
  [16] U1I10_AU0 — clear uab1_vin10 to acore_u0
  [15] U1I10_U3O1 — clear uab1_vin10 to uab3_vout1
  [13] U1I10_C3O1 — clear uab1_vin10 to ctb3_vout1
  [10] U1I10_U2O0 — clear uab1_vin10 to uab2_vout0
  [7] U1I10_U1O1 — clear uab1_vin10 to uab1_vout1
  [4] U1I10_C1O0 — clear uab1_vin10 to ctb1_vout0
  [3] U1I10_U0O1 — clear uab1_vin10 to uab0_vout1
  [1] U1I10_C0O1 — clear uab1_vin10 to ctb0_vout1
0x1A8 UAB1VIN11_SW — uab1_vin11 switch control
  [31] U1I11_C1C3 — connect uab1_vin11 to ctb1_ctbus3
  [21] U1I11_AU5 — connect uab1_vin11 to acore_u5
  [19] U1I11_AU3 — connect uab1_vin11 to acore_u3
  [17] U1I11_AU1 — connect uab1_vin11 to acore_u1
  [12] U1I11_C3O0 — connect uab1_vin11 to ctb3_vout0
  [11] U1I11_U2O1 — connect uab1_vin11 to uab2_vout1
  [9] U1I11_C2O1 — connect uab1_vin11 to ctb2_vout1
  [6] U1I11_U1O0 — connect uab1_vin11 to uab1_vout0
  [0] U1I11_C0O0 — connect uab1_vin11 to ctb0_vout0
0x1AC UAB1VIN11_SW_CLR — uab1_vin11 switch control clear
  [31] U1I11_C1C3 — clear uab1_vin11 to ctb1_ctbus3
  [21] U1I11_AU5 — clear uab1_vin11 to acore_u5
  [19] U1I11_AU3 — clear uab1_vin11 to acore_u3
  [17] U1I11_AU1 — clear uab1_vin11 to acore_u1
  [12] U1I11_C3O0 — clear uab1_vin11 to ctb3_vout0
  [11] U1I11_U2O1 — clear uab1_vin11 to uab2_vout1
  [9] U1I11_C2O1 — clear uab1_vin11 to ctb2_vout1
  [6] U1I11_U1O0 — clear uab1_vin11 to uab1_vout0
  [0] U1I11_C0O0 — clear uab1_vin11 to ctb0_vout0
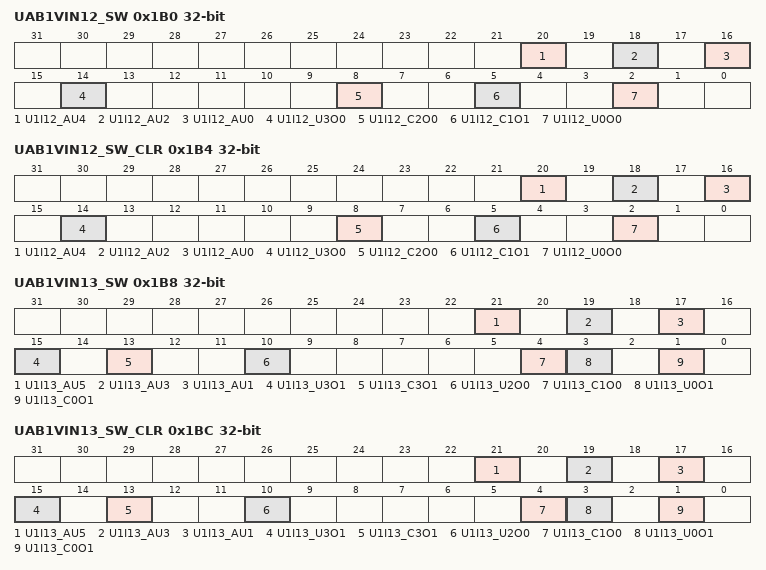
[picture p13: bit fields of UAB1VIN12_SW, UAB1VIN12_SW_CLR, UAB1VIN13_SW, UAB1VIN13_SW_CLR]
0x1B0 UAB1VIN12_SW — uab1_vin12 switch control
  [20] U1I12_AU4 — connect uab1_vin12 to acore_u4
  [18] U1I12_AU2 — connect uab1_vin12 to acore_u2
  [16] U1I12_AU0 — connect uab1_vin12 to acore_u0
  [14] U1I12_U3O0 — connect uab1_vin12 to uab3_vout0
  [8] U1I12_C2O0 — connect uab1_vin12 to ctb2_vout0
  [5] U1I12_C1O1 — connect uab1_vin12 to ctb1_vout1
  [2] U1I12_U0O0 — connect uab1_vin12 to uab0_vout0
0x1B4 UAB1VIN12_SW_CLR — uab1_vin12 switch control clear
  [20] U1I12_AU4 — clear uab1_vin12 to acore_u4
  [18] U1I12_AU2 — clear uab1_vin12 to acore_u2
  [16] U1I12_AU0 — clear uab1_vin12 to acore_u0
  [14] U1I12_U3O0 — clear uab1_vin12 to uab3_vout0
  [8] U1I12_C2O0 — clear uab1_vin12 to ctb2_vout0
  [5] U1I12_C1O1 — clear uab1_vin12 to ctb1_vout1
  [2] U1I12_U0O0 — clear uab1_vin12 to uab0_vout0
0x1B8 UAB1VIN13_SW — uab1_vin13 switch control
  [21] U1I13_AU5 — connect uab1_vin13 to acore_u5
  [19] U1I13_AU3 — connect uab1_vin13 to acore_u3
  [17] U1I13_AU1 — connect uab1_vin13 to acore_u1
  [15] U1I13_U3O1 — connect uab1_vin13 to uab3_vout1
  [13] U1I13_C3O1 — connect uab1_vin13 to ctb3_vout1
  [10] U1I13_U2O0 — connect uab1_vin13 to uab2_vout0
  [4] U1I13_C1O0 — connect uab1_vin13 to ctb1_vout0
  [3] U1I13_U0O1 — connect uab1_vin13 to uab0_vout1
  [1] U1I13_C0O1 — connect uab1_vin13 to ctb0_vout1
0x1BC UAB1VIN13_SW_CLR — uab1_vin13 switch control clear
  [21] U1I13_AU5 — clear uab1_vin13 to acore_u5
  [19] U1I13_AU3 — clear uab1_vin13 to acore_u3
  [17] U1I13_AU1 — clear uab1_vin13 to acore_u1
  [15] U1I13_U3O1 — clear uab1_vin13 to uab3_vout1
  [13] U1I13_C3O1 — clear uab1_vin13 to ctb3_vout1
  [10] U1I13_U2O0 — clear uab1_vin13 to uab2_vout0
  [4] U1I13_C1O0 — clear uab1_vin13 to ctb1_vout0
  [3] U1I13_U0O1 — clear uab1_vin13 to uab0_vout1
  [1] U1I13_C0O1 — clear uab1_vin13 to ctb0_vout1
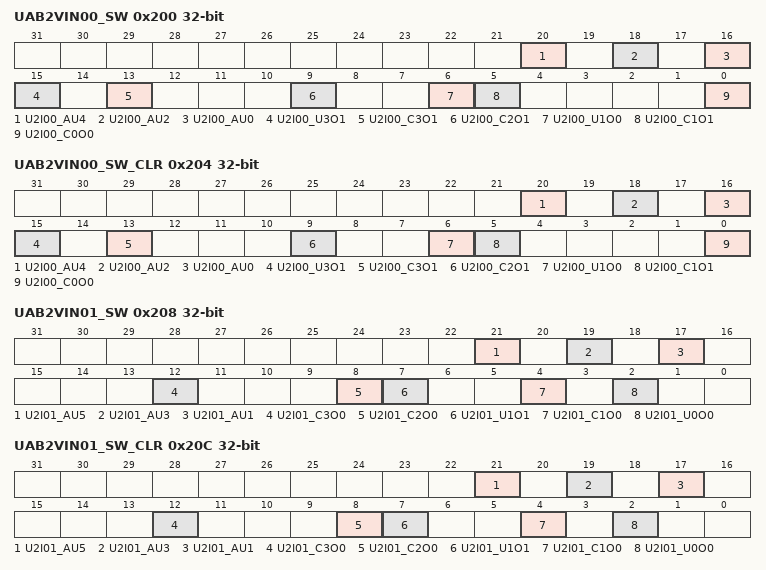
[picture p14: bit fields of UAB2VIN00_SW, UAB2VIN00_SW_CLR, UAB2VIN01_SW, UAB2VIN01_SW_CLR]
0x200 UAB2VIN00_SW — uab2_vin00 switch control
  [20] U2I00_AU4 — connect uab2_vin00 to acore_u4
  [18] U2I00_AU2 — connect uab2_vin00 to acore_u2
  [16] U2I00_AU0 — connect uab2_vin00 to acore_u0
  [15] U2I00_U3O1 — connect uab2_vin00 to uab3_vout1
  [13] U2I00_C3O1 — connect uab2_vin00 to ctb3_vout1
  [9] U2I00_C2O1 — connect uab2_vin00 to ctb2_vout1
  [6] U2I00_U1O0 — connect uab2_vin00 to uab1_vout0
  [5] U2I00_C1O1 — connect uab2_vin00 to ctb1_vout1
  [0] U2I00_C0O0 — connect uab2_vin00 to ctb0_vout0
0x204 UAB2VIN00_SW_CLR — uab2_vin00 switch control clear
  [20] U2I00_AU4 — clear uab2_vin00 to acore_u4
  [18] U2I00_AU2 — clear uab2_vin00 to acore_u2
  [16] U2I00_AU0 — clear uab2_vin00 to acore_u0
  [15] U2I00_U3O1 — clear uab2_vin00 to uab3_vout1
  [13] U2I00_C3O1 — clear uab2_vin00 to ctb3_vout1
  [9] U2I00_C2O1 — clear uab2_vin00 to ctb2_vout1
  [6] U2I00_U1O0 — clear uab2_vin00 to uab1_vout0
  [5] U2I00_C1O1 — clear uab2_vin00 to ctb1_vout1
  [0] U2I00_C0O0 — clear uab2_vin00 to ctb0_vout0
0x208 UAB2VIN01_SW — uab2_vin01 switch control
  [21] U2I01_AU5 — connect uab2_vin01 to acore_u5
  [19] U2I01_AU3 — connect uab2_vin01 to acore_u3
  [17] U2I01_AU1 — connect uab2_vin01 to acore_u1
  [12] U2I01_C3O0 — connect uab2_vin01 to ctb3_vout0
  [8] U2I01_C2O0 — connect uab2_vin01 to ctb2_vout0
  [7] U2I01_U1O1 — connect uab2_vin01 to uab1_vout1
  [4] U2I01_C1O0 — connect uab2_vin01 to ctb1_vout0
  [2] U2I01_U0O0 — connect uab2_vin01 to uab0_vout0
0x20C UAB2VIN01_SW_CLR — uab2_vin01 switch control clear
  [21] U2I01_AU5 — clear uab2_vin01 to acore_u5
  [19] U2I01_AU3 — clear uab2_vin01 to acore_u3
  [17] U2I01_AU1 — clear uab2_vin01 to acore_u1
  [12] U2I01_C3O0 — clear uab2_vin01 to ctb3_vout0
  [8] U2I01_C2O0 — clear uab2_vin01 to ctb2_vout0
  [7] U2I01_U1O1 — clear uab2_vin01 to uab1_vout1
  [4] U2I01_C1O0 — clear uab2_vin01 to ctb1_vout0
  [2] U2I01_U0O0 — clear uab2_vin01 to uab0_vout0
0x210 UAB2VIN02_SW — uab2_vin02 switch control
  [31] U2I02_C2C2 — connect uab2_vin02 to ctb2_ctbus2
  [20] U2I02_AU4 — connect uab2_vin02 to acore_u4
  [18] U2I02_AU2 — connect uab2_vin02 to acore_u2
  [16] U2I02_AU0 — connect uab2_vin02 to acore_u0
  [14] U2I02_U3O0 — connect uab2_vin02 to uab3_vout0
  [11] U2I02_U2O1 — connect uab2_vin02 to uab2_vout1
  [3] U2I02_U0O1 — connect uab2_vin02 to uab0_vout1
  [1] U2I02_C0O1 — connect uab2_vin02 to ctb0_vout1
0x214 UAB2VIN02_SW_CLR — uab2_vin02 switch control clear
  [31] U2I02_C2C2 — clear uab2_vin02 to ctb2_ctbus2
  [20] U2I02_AU4 — clear uab2_vin02 to acore_u4
  [18] U2I02_AU2 — clear uab2_vin02 to acore_u2
  [16] U2I02_AU0 — clear uab2_vin02 to acore_u0
  [14] U2I02_U3O0 — clear uab2_vin02 to uab3_vout0
  [11] U2I02_U2O1 — clear uab2_vin02 to uab2_vout1
  [3] U2I02_U0O1 — clear uab2_vin02 to uab0_vout1
  [1] U2I02_C0O1 — clear uab2_vin02 to ctb0_vout1
0x218 UAB2VIN03_SW — uab2_vin03 switch control
  [31] U2I03_C2C1 — connect uab2_vin03 to ctb2_ctbus1
  [30] U2I03_U2I10 — connect uab2_vin03 to uab2_vin10
  [21] U2I03_AU5 — connect uab2_vin03 to acore_u5
  [19] U2I03_AU3 — connect uab2_vin03 to acore_u3
  [17] U2I03_AU1 — connect uab2_vin03 to acore_u1
  [15] U2I03_U3O1 — connect uab2_vin03 to uab3_vout1
  [13] U2I03_C3O1 — connect uab2_vin03 to ctb3_vout1
  [10] U2I03_U2O0 — connect uab2_vin03 to uab2_vout0
  [9] U2I03_C2O1 — connect uab2_vin03 to ctb2_vout1
  [6] U2I03_U1O0 — connect uab2_vin03 to uab1_vout0
  [5] U2I03_C1O1 — connect uab2_vin03 to ctb1_vout1
  [0] U2I03_C0O0 — connect uab2_vin03 to ctb0_vout0
0x21C UAB2VIN03_SW_CLR — uab2_vin03 switch control clear
  [31] U2I03_C2C1 — clear uab2_vin03 to ctb2_ctbus1
  [30] U2I03_U2I10 — clear uab2_vin03 to uab2_vin10
  [21] U2I03_AU5 — clear uab2_vin03 to acore_u5
  [19] U2I03_AU3 — clear uab2_vin03 to acore_u3
  [17] U2I03_AU1 — clear uab2_vin03 to acore_u1
  [15] U2I03_U3O1 — clear uab2_vin03 to uab3_vout1
  [13] U2I03_C3O1 — clear uab2_vin03 to ctb3_vout1
  [10] U2I03_U2O0 — clear uab2_vin03 to uab2_vout0
  [9] U2I03_C2O1 — clear uab2_vin03 to ctb2_vout1
  [6] U2I03_U1O0 — clear uab2_vin03 to uab1_vout0
  [5] U2I03_C1O1 — clear uab2_vin03 to ctb1_vout1
  [0] U2I03_C0O0 — clear uab2_vin03 to ctb0_vout0
0x220 UAB2VIN10_SW — uab2_vin10 switch control
  [31] U2I10_C2C0 — connect uab2_vin10 to ctb2_ctbus0
  [20] U2I10_AU4 — connect uab2_vin10 to acore_u4
  [18] U2I10_AU2 — connect uab2_vin10 to acore_u2
  [16] U2I10_AU0 — connect uab2_vin10 to acore_u0
  [12] U2I10_C3O0 — connect uab2_vin10 to ctb3_vout0
  [11] U2I10_U2O1 — connect uab2_vin10 to uab2_vout1
  [8] U2I10_C2O0 — connect uab2_vin10 to ctb2_vout0
  [7] U2I10_U1O1 — connect uab2_vin10 to uab1_vout1
  [4] U2I10_C1O0 — connect uab2_vin10 to ctb1_vout0
  [2] U2I10_U0O0 — connect uab2_vin10 to uab0_vout0
0x224 UAB2VIN10_SW_CLR — uab2_vin10 switch control clear
  [31] U2I10_C2C0 — clear uab2_vin10 to ctb2_ctbus0
  [20] U2I10_AU4 — clear uab2_vin10 to acore_u4
  [18] U2I10_AU2 — clear uab2_vin10 to acore_u2
  [16] U2I10_AU0 — clear uab2_vin10 to acore_u0
  [12] U2I10_C3O0 — clear uab2_vin10 to ctb3_vout0
  [11] U2I10_U2O1 — clear uab2_vin10 to uab2_vout1
  [8] U2I10_C2O0 — clear uab2_vin10 to ctb2_vout0
  [7] U2I10_U1O1 — clear uab2_vin10 to uab1_vout1
  [4] U2I10_C1O0 — clear uab2_vin10 to ctb1_vout0
  [2] U2I10_U0O0 — clear uab2_vin10 to uab0_vout0
0x228 UAB2VIN11_SW — uab2_vin11 switch control
  [31] U2I11_C2C3 — connect uab2_vin11 to ctb2_ctbus3
  [21] U2I11_AU5 — connect uab2_vin11 to acore_u5
  [19] U2I11_AU3 — connect uab2_vin11 to acore_u3
  [17] U2I11_AU1 — connect uab2_vin11 to acore_u1
  [14] U2I11_U3O0 — connect uab2_vin11 to uab3_vout0
  [10] U2I11_U2O0 — connect uab2_vin11 to uab2_vout0
  [3] U2I11_U0O1 — connect uab2_vin11 to uab0_vout1
  [1] U2I11_C0O1 — connect uab2_vin11 to ctb0_vout1
0x22C UAB2VIN11_SW_CLR — uab2_vin11 switch control clear
  [31] U2I11_C2C3 — clear uab2_vin11 to ctb2_ctbus3
  [21] U2I11_AU5 — clear uab2_vin11 to acore_u5
  [19] U2I11_AU3 — clear uab2_vin11 to acore_u3
  [17] U2I11_AU1 — clear uab2_vin11 to acore_u1
  [14] U2I11_U3O0 — clear uab2_vin11 to uab3_vout0
  [10] U2I11_U2O0 — clear uab2_vin11 to uab2_vout0
  [3] U2I11_U0O1 — clear uab2_vin11 to uab0_vout1
  [1] U2I11_C0O1 — clear uab2_vin11 to ctb0_vout1
0x230 UAB2VIN12_SW — uab2_vin12 switch control
  [20] U2I12_AU4 — connect uab2_vin12 to acore_u4
  [18] U2I12_AU2 — connect uab2_vin12 to acore_u2
  [16] U2I12_AU0 — connect uab2_vin12 to acore_u0
  [15] U2I12_U3O1 — connect uab2_vin12 to uab3_vout1
  [13] U2I12_C3O1 — connect uab2_vin12 to ctb3_vout1
  [9] U2I12_C2O1 — connect uab2_vin12 to ctb2_vout1
  [6] U2I12_U1O0 — connect uab2_vin12 to uab1_vout0
  [5] U2I12_C1O1 — connect uab2_vin12 to ctb1_vout1
  [0] U2I12_C0O0 — connect uab2_vin12 to ctb0_vout0
0x234 UAB2VIN12_SW_CLR — uab2_vin12 switch control clear
  [20] U2I12_AU4 — clear uab2_vin12 to acore_u4
  [18] U2I12_AU2 — clear uab2_vin12 to acore_u2
  [16] U2I12_AU0 — clear uab2_vin12 to acore_u0
  [15] U2I12_U3O1 — clear uab2_vin12 to uab3_vout1
  [13] U2I12_C3O1 — clear uab2_vin12 to ctb3_vout1
  [9] U2I12_C2O1 — clear uab2_vin12 to ctb2_vout1
  [6] U2I12_U1O0 — clear uab2_vin12 to uab1_vout0
  [5] U2I12_C1O1 — clear uab2_vin12 to ctb1_vout1
  [0] U2I12_C0O0 — clear uab2_vin12 to ctb0_vout0
0x238 UAB2VIN13_SW — uab2_vin13 switch control
  [21] U2I13_AU5 — connect uab2_vin13 to acore_u5
  [19] U2I13_AU3 — connect uab2_vin13 to acore_u3
  [17] U2I13_AU1 — connect uab2_vin13 to acore_u1
  [12] U2I13_C3O0 — connect uab2_vin13 to ctb3_vout0
  [8] U2I13_C2O0 — connect uab2_vin13 to ctb2_vout0
  [7] U2I13_U1O1 — connect uab2_vin13 to uab1_vout1
  [2] U2I13_U0O0 — connect uab2_vin13 to uab0_vout0
0x23C UAB2VIN13_SW_CLR — uab2_vin13 switch control clear
  [21] U2I13_AU5 — clear uab2_vin13 to acore_u5
  [19] U2I13_AU3 — clear uab2_vin13 to acore_u3
  [17] U2I13_AU1 — clear uab2_vin13 to acore_u1
  [12] U2I13_C3O0 — clear uab2_vin13 to ctb3_vout0
  [8] U2I13_C2O0 — clear uab2_vin13 to ctb2_vout0
  [7] U2I13_U1O1 — clear uab2_vin13 to uab1_vout1
  [2] U2I13_U0O0 — clear uab2_vin13 to uab0_vout0
0x280 UAB3VIN00_SW — uab3_vin00 switch control
  [21] U3I00_AU5 — connect uab3_vin00 to acore_u5
  [19] U3I00_AU3 — connect uab3_vin00 to acore_u3
  [17] U3I00_AU1 — connect uab3_vin00 to acore_u1
  [13] U3I00_C3O1 — connect uab3_vin00 to ctb3_vout1
  [10] U3I00_U2O0 — connect uab3_vin00 to uab2_vout0
  [9] U3I00_C2O1 — connect uab3_vin00 to ctb2_vout1
  [4] U3I00_C1O0 — connect uab3_vin00 to ctb1_vout0
  [3] U3I00_U0O1 — connect uab3_vin00 to uab0_vout1
  [1] U3I00_C0O1 — connect uab3_vin00 to ctb0_vout1
0x284 UAB3VIN00_SW_CLR — uab3_vin00 switch control clear
  [21] U3I00_AU5 — clear uab3_vin00 to acore_u5
  [19] U3I00_AU3 — clear uab3_vin00 to acore_u3
  [17] U3I00_AU1 — clear uab3_vin00 to acore_u1
  [13] U3I00_C3O1 — clear uab3_vin00 to ctb3_vout1
  [10] U3I00_U2O0 — clear uab3_vin00 to uab2_vout0
  [9] U3I00_C2O1 — clear uab3_vin00 to ctb2_vout1
  [4] U3I00_C1O0 — clear uab3_vin00 to ctb1_vout0
  [3] U3I00_U0O1 — clear uab3_vin00 to uab0_vout1
  [1] U3I00_C0O1 — clear uab3_vin00 to ctb0_vout1
0x288 UAB3VIN01_SW — uab3_vin01 switch control
  [20] U3I01_AU4 — connect uab3_vin01 to acore_u4
  [18] U3I01_AU2 — connect uab3_vin01 to acore_u2
  [16] U3I01_AU0 — connect uab3_vin01 to acore_u0
  [12] U3I01_C3O0 — connect uab3_vin01 to ctb3_vout0
  [11] U3I01_U2O1 — connect uab3_vin01 to uab2_vout1
  [8] U3I01_C2O0 — connect uab3_vin01 to ctb2_vout0
  [6] U3I01_U1O0 — connect uab3_vin01 to uab1_vout0
  [0] U3I01_C0O0 — connect uab3_vin01 to ctb0_vout0
0x28C UAB3VIN01_SW_CLR — uab3_vin01 switch control clear
  [20] U3I01_AU4 — clear uab3_vin01 to acore_u4
  [18] U3I01_AU2 — clear uab3_vin01 to acore_u2
  [16] U3I01_AU0 — clear uab3_vin01 to acore_u0
  [12] U3I01_C3O0 — clear uab3_vin01 to ctb3_vout0
  [11] U3I01_U2O1 — clear uab3_vin01 to uab2_vout1
  [8] U3I01_C2O0 — clear uab3_vin01 to ctb2_vout0
  [6] U3I01_U1O0 — clear uab3_vin01 to uab1_vout0
  [0] U3I01_C0O0 — clear uab3_vin01 to ctb0_vout0
0x290 UAB3VIN02_SW — uab3_vin02 switch control
  [31] U3I02_C3C2 — connect uab3_vin02 to ctb3_ctbus2
  [21] U3I02_AU5 — connect uab3_vin02 to acore_u5
  [19] U3I02_AU3 — connect uab3_vin02 to acore_u3
  [17] U3I02_AU1 — connect uab3_vin02 to acore_u1
  [15] U3I02_U3O1 — connect uab3_vin02 to uab3_vout1
  [7] U3I02_U1O1 — connect uab3_vin02 to uab1_vout1
  [5] U3I02_C1O1 — connect uab3_vin02 to ctb1_vout1
  [2] U3I02_U0O0 — connect uab3_vin02 to uab0_vout0
0x294 UAB3VIN02_SW_CLR — uab3_vin02 switch control clear
  [31] U3I02_C3C2 — clear uab3_vin02 to ctb3_ctbus2
  [21] U3I02_AU5 — clear uab3_vin02 to acore_u5
  [19] U3I02_AU3 — clear uab3_vin02 to acore_u3
  [17] U3I02_AU1 — clear uab3_vin02 to acore_u1
  [15] U3I02_U3O1 — clear uab3_vin02 to uab3_vout1
  [7] U3I02_U1O1 — clear uab3_vin02 to uab1_vout1
  [5] U3I02_C1O1 — clear uab3_vin02 to ctb1_vout1
  [2] U3I02_U0O0 — clear uab3_vin02 to uab0_vout0
0x298 UAB3VIN03_SW — uab3_vin03 switch control
  [31] U3I03_C3C1 — connect uab3_vin03 to ctb3_ctbus1
  [30] U3I03_U3I10 — connect uab3_vin03 to uab3_vin10
  [20] U3I03_AU4 — connect uab3_vin03 to acore_u4
  [18] U3I03_AU2 — connect uab3_vin03 to acore_u2
  [16] U3I03_AU0 — connect uab3_vin03 to acore_u0
  [14] U3I03_U3O0 — connect uab3_vin03 to uab3_vout0
  [13] U3I03_C3O1 — connect uab3_vin03 to ctb3_vout1
  [10] U3I03_U2O0 — connect uab3_vin03 to uab2_vout0
  [9] U3I03_C2O1 — connect uab3_vin03 to ctb2_vout1
  [4] U3I03_C1O0 — connect uab3_vin03 to ctb1_vout0
  [3] U3I03_U0O1 — connect uab3_vin03 to uab0_vout1
  [1] U3I03_C0O1 — connect uab3_vin03 to ctb0_vout1
0x29C UAB3VIN03_SW_CLR — uab3_vin03 switch control clear
  [31] U3I03_C3C1 — clear uab3_vin03 to ctb3_ctbus1
  [30] U3I03_U3I10 — clear uab3_vin03 to uab3_vin10
  [20] U3I03_AU4 — clear uab3_vin03 to acore_u4
  [18] U3I03_AU2 — clear uab3_vin03 to acore_u2
  [16] U3I03_AU0 — clear uab3_vin03 to acore_u0
  [14] U3I03_U3O0 — clear uab3_vin03 to uab3_vout0
  [13] U3I03_C3O1 — clear uab3_vin03 to ctb3_vout1
  [10] U3I03_U2O0 — clear uab3_vin03 to uab2_vout0
  [9] U3I03_C2O1 — clear uab3_vin03 to ctb2_vout1
  [4] U3I03_C1O0 — clear uab3_vin03 to ctb1_vout0
  [3] U3I03_U0O1 — clear uab3_vin03 to uab0_vout1
  [1] U3I03_C0O1 — clear uab3_vin03 to ctb0_vout1
0x2A0 UAB3VIN10_SW — uab3_vin10 switch control
  [31] U3I10_C3C0 — connect uab3_vin10 to ctb3_ctbus0
  [21] U3I10_AU5 — connect uab3_vin10 to acore_u5
  [19] U3I10_AU3 — connect uab3_vin10 to acore_u3
  [17] U3I10_AU1 — connect uab3_vin10 to acore_u1
  [15] U3I10_U3O1 — connect uab3_vin10 to uab3_vout1
  [12] U3I10_C3O0 — connect uab3_vin10 to ctb3_vout0
  [11] U3I10_U2O1 — connect uab3_vin10 to uab2_vout1
  [8] U3I10_C2O0 — connect uab3_vin10 to ctb2_vout0
  [6] U3I10_U1O0 — connect uab3_vin10 to uab1_vout0
  [0] U3I10_C0O0 — connect uab3_vin10 to ctb0_vout0
0x2A4 UAB3VIN10_SW_CLR — uab3_vin10 switch control clear
  [31] U3I10_C3C0 — clear uab3_vin10 to ctb3_ctbus0
  [21] U3I10_AU5 — clear uab3_vin10 to acore_u5
  [19] U3I10_AU3 — clear uab3_vin10 to acore_u3
  [17] U3I10_AU1 — clear uab3_vin10 to acore_u1
  [15] U3I10_U3O1 — clear uab3_vin10 to uab3_vout1
  [12] U3I10_C3O0 — clear uab3_vin10 to ctb3_vout0
  [11] U3I10_U2O1 — clear uab3_vin10 to uab2_vout1
  [8] U3I10_C2O0 — clear uab3_vin10 to ctb2_vout0
  [6] U3I10_U1O0 — clear uab3_vin10 to uab1_vout0
  [0] U3I10_C0O0 — clear uab3_vin10 to ctb0_vout0
0x2A8 UAB3VIN11_SW — uab3_vin11 switch control
  [31] U3I11_C3C3 — connect uab3_vin11 to ctb3_ctbus3
  [20] U3I11_AU4 — connect uab3_vin11 to acore_u4
  [18] U3I11_AU2 — connect uab3_vin11 to acore_u2
  [16] U3I11_AU0 — connect uab3_vin11 to acore_u0
  [14] U3I11_U3O0 — connect uab3_vin11 to uab3_vout0
  [7] U3I11_U1O1 — connect uab3_vin11 to uab1_vout1
  [5] U3I11_C1O1 — connect uab3_vin11 to ctb1_vout1
  [2] U3I11_U0O0 — connect uab3_vin11 to uab0_vout0
0x2AC UAB3VIN11_SW_CLR — uab3_vin11 switch control clear
  [31] U3I11_C3C3 — clear uab3_vin11 to ctb3_ctbus3
  [20] U3I11_AU4 — clear uab3_vin11 to acore_u4
  [18] U3I11_AU2 — clear uab3_vin11 to acore_u2
  [16] U3I11_AU0 — clear uab3_vin11 to acore_u0
  [14] U3I11_U3O0 — clear uab3_vin11 to uab3_vout0
  [7] U3I11_U1O1 — clear uab3_vin11 to uab1_vout1
  [5] U3I11_C1O1 — clear uab3_vin11 to ctb1_vout1
  [2] U3I11_U0O0 — clear uab3_vin11 to uab0_vout0
0x2B0 UAB3VIN12_SW — uab3_vin12 switch control
  [21] U3I12_AU5 — connect uab3_vin12 to acore_u5
  [19] U3I12_AU3 — connect uab3_vin12 to acore_u3
  [17] U3I12_AU1 — connect uab3_vin12 to acore_u1
  [13] U3I12_C3O1 — connect uab3_vin12 to ctb3_vout1
  [10] U3I12_U2O0 — connect uab3_vin12 to uab2_vout0
  [9] U3I12_C2O1 — connect uab3_vin12 to ctb2_vout1
  [4] U3I12_C1O0 — connect uab3_vin12 to ctb1_vout0
  [3] U3I12_U0O1 — connect uab3_vin12 to uab0_vout1
  [1] U3I12_C0O1 — connect uab3_vin12 to ctb0_vout1
0x2B4 UAB3VIN12_SW_CLR — uab3_vin12 switch control clear
  [21] U3I12_AU5 — clear uab3_vin12 to acore_u5
  [19] U3I12_AU3 — clear uab3_vin12 to acore_u3
  [17] U3I12_AU1 — clear uab3_vin12 to acore_u1
  [13] U3I12_C3O1 — clear uab3_vin12 to ctb3_vout1
  [10] U3I12_U2O0 — clear uab3_vin12 to uab2_vout0
  [9] U3I12_C2O1 — clear uab3_vin12 to ctb2_vout1
  [4] U3I12_C1O0 — clear uab3_vin12 to ctb1_vout0
  [3] U3I12_U0O1 — clear uab3_vin12 to uab0_vout1
  [1] U3I12_C0O1 — clear uab3_vin12 to ctb0_vout1
0x2B8 UAB3VIN13_SW — uab3_vin13 switch control
  [20] U3I13_AU4 — connect uab3_vin13 to acore_u4
  [18] U3I13_AU2 — connect uab3_vin13 to acore_u2
  [16] U3I13_AU0 — connect uab3_vin13 to acore_u0
  [12] U3I13_C3O0 — connect uab3_vin13 to ctb3_vout0
  [11] U3I13_U2O1 — connect uab3_vin13 to uab2_vout1
  [6] U3I13_U1O0 — connect uab3_vin13 to uab1_vout0
  [0] U3I13_C0O0 — connect uab3_vin13 to ctb0_vout0
0x2BC UAB3VIN13_SW_CLR — uab3_vin13 switch control clear
  [20] U3I13_AU4 — clear uab3_vin13 to acore_u4
  [18] U3I13_AU2 — clear uab3_vin13 to acore_u2
  [16] U3I13_AU0 — clear uab3_vin13 to acore_u0
  [12] U3I13_C3O0 — clear uab3_vin13 to ctb3_vout0
  [11] U3I13_U2O1 — clear uab3_vin13 to uab2_vout1
  [6] U3I13_U1O0 — clear uab3_vin13 to uab1_vout0
  [0] U3I13_C0O0 — clear uab3_vin13 to ctb0_vout0
